VERSION ""

NS_ :

BS_:

BU_: INV U2C VCU BMS INV BMS VCU

BO_ 3221225472 VECTOR__INDEPENDENT_SIG_MSG: 0 Vector__XXX
 SG_ INV_Buffer_Record : 0|8@1+ (1,0) [0|255] "" Vector__XXX
 SG_ INV_Buffer_Segment : 8|8@1+ (1,0) [0|5] "" Vector__XXX
 SG_ INV_Diag_Data_1 : 16|16@1- (1,0) [-32768|32767] "" Vector__XXX
 SG_ INV_Diag_Data_2 : 32|16@1- (1,0) [-32768|32767] "" Vector__XXX
 SG_ INV_Diag_Data_3 : 48|16@1- (1,0) [-32768|32767] "" Vector__XXX

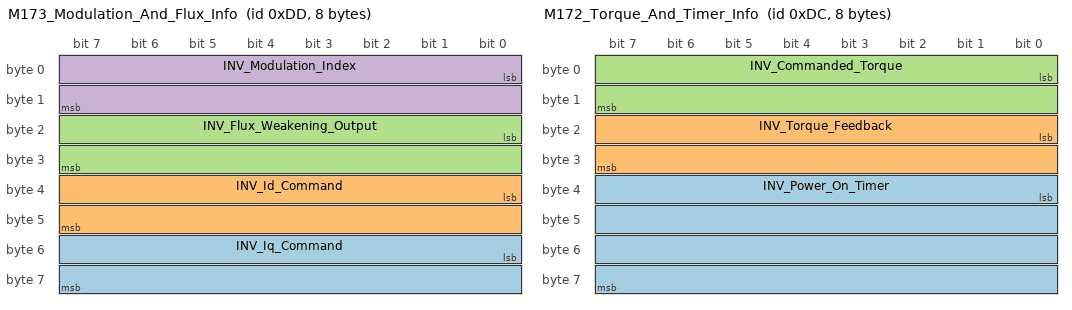
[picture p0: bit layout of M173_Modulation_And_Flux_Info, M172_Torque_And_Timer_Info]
BO_ 221 M173_Modulation_And_Flux_Info: 8 INV
 SG_ INV_Iq_Command : 48|16@1- (0.1,0) [-3276.8|3276.7] "current:A" Vector__XXX
 SG_ INV_Id_Command : 32|16@1- (0.1,0) [-3276.8|3276.7] "current:A" Vector__XXX
 SG_ INV_Flux_Weakening_Output : 16|16@1- (0.1,0) [-3276.8|3276.7] "current:A" Vector__XXX
 SG_ INV_Modulation_Index : 0|16@1- (0.0001,0) [0|3.2767] "" Vector__XXX

BO_ 220 M172_Torque_And_Timer_Info: 8 INV
 SG_ INV_Power_On_Timer : 32|32@1+ (0.003,0) [0|12884800] "time:sec" Vector__XXX
 SG_ INV_Torque_Feedback : 16|16@1- (0.1,0) [-3276.8|3276.7] "torque:N.m" Vector__XXX
 SG_ INV_Commanded_Torque : 0|16@1- (0.1,0) [-3276.8|3276.7] "torque:N.m" Vector__XXX

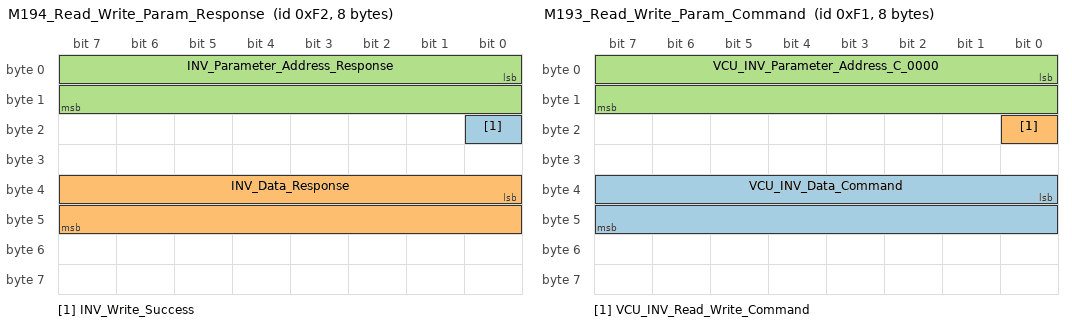
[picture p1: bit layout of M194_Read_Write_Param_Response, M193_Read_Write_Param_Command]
BO_ 242 M194_Read_Write_Param_Response: 8 INV
 SG_ INV_Write_Success : 16|1@1+ (1,0) [0|1] "" Vector__XXX
 SG_ INV_Data_Response : 32|16@1- (1,0) [-32768|32767] "" Vector__XXX
 SG_ INV_Parameter_Address_Response : 0|16@1+ (1,0) [0|65535] "" Vector__XXX

BO_ 241 M193_Read_Write_Param_Command: 8 VCU
 SG_ VCU_INV_Data_Command : 32|16@1- (1,0) [-32768|32767] "" Vector__XXX
 SG_ VCU_INV_Read_Write_Command : 16|1@1+ (1,0) [0|1] "" Vector__XXX
 SG_ VCU_INV_Parameter_Address_C_0000 : 0|16@1+ (1,0) [0|65535] "" Vector__XXX

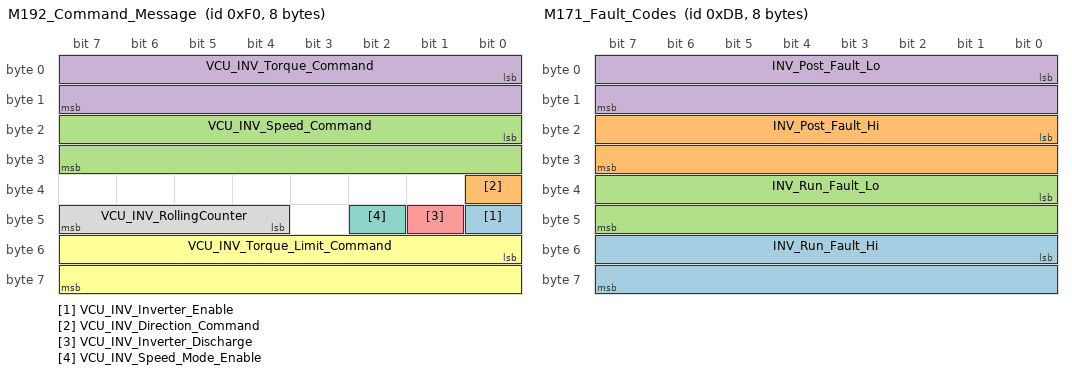
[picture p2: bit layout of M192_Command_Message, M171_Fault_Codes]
BO_ 240 M192_Command_Message: 8 VCU
 SG_ VCU_INV_Inverter_Enable : 40|1@1+ (1,0) [0|1] "" Vector__XXX
 SG_ VCU_INV_Direction_Command : 32|1@1+ (1,0) [0|1] "" Vector__XXX
 SG_ VCU_INV_Speed_Command : 16|16@1- (1,0) [-32768|32767] "angular_speed:rpm" Vector__XXX
 SG_ VCU_INV_Torque_Command : 0|16@1- (0.1,0) [-3276.8|3276.7] "torque:N.m" Vector__XXX
 SG_ VCU_INV_Inverter_Discharge : 41|1@1+ (1,0) [0|1] "" Vector__XXX
 SG_ VCU_INV_Torque_Limit_Command : 48|16@1- (0.1,0) [-3276.8|3276.7] "torque:N.m" Vector__XXX
 SG_ VCU_INV_Speed_Mode_Enable : 42|1@1+ (1,0) [0|1] "" Vector__XXX
 SG_ VCU_INV_RollingCounter : 44|4@1+ (1,0) [0|15] "" Vector__XXX

BO_ 219 M171_Fault_Codes: 8 INV
 SG_ INV_Run_Fault_Hi : 48|16@1+ (1,0) [0|65535] "" Vector__XXX
 SG_ INV_Post_Fault_Hi : 16|16@1+ (1,0) [0|65535] "" Vector__XXX
 SG_ INV_Run_Fault_Lo : 32|16@1+ (1,0) [0|65535] "" Vector__XXX
 SG_ INV_Post_Fault_Lo : 0|16@1+ (1,0) [0|65535] "" Vector__XXX

BO_ 218 M170_Internal_States: 8 INV
 SG_ INV_Direction_Command : 56|1@1+ (1,0) [0|1] "" Vector__XXX
 SG_ INV_Inverter_Enable_State : 48|1@1+ (1,0) [0|1] "" Vector__XXX
 SG_ INV_Relay_3_Status : 26|1@1+ (1,0) [0|1] "" Vector__XXX
 SG_ INV_Relay_4_Status : 27|1@1+ (1,0) [0|1] "" Vector__XXX
 SG_ INV_Relay_2_Status : 25|1@1+ (1,0) [0|1] "" Vector__XXX
 SG_ INV_Inverter_Run_Mode : 32|1@1+ (1,0) [0|1] "" Vector__XXX
 SG_ INV_Inverter_Command_Mode : 40|1@1+ (1,0) [0|1] "" Vector__XXX
 SG_ INV_Relay_1_Status : 24|1@1+ (1,0) [0|1] "" Vector__XXX
 SG_ INV_Inverter_State : 16|8@1+ (1,0) [0|255] "" Vector__XXX
 SG_ INV_VSM_State : 0|8@1+ (1,0) [0|15] "" Vector__XXX
 SG_ INV_Inverter_Enable_Lockout : 55|1@1+ (1,0) [0|1] "" Vector__XXX
 SG_ INV_Inverter_Discharge_State : 37|3@1+ (1,0) [0|7] "" Vector__XXX
 SG_ INV_Relay_5_Status : 28|1@1+ (1,0) [0|1] "" Vector__XXX
 SG_ INV_Relay_6_Status : 29|1@1+ (1,0) [0|1] "" Vector__XXX
 SG_ INV_BMS_Active : 57|1@1+ (1,0) [0|1] "" Vector__XXX
 SG_ INV_BMS_Torque_Limiting : 58|1@1+ (1,0) [0|1] "" Vector__XXX
 SG_ INV_Max_Speed_Limiting : 59|1@1+ (1,0) [0|1] "" Vector__XXX
 SG_ INV_Low_Speed_Limiting : 61|1@1+ (1,0) [0|1] "" Vector__XXX
 SG_ INV_Rolling_Counter : 44|4@1+ (1,0) [0|15] "" Vector__XXX
 SG_ INV_PWM_Frequency : 8|8@1+ (1,0) [0|255] "kHz" Vector__XXX
 SG_ INV_Start_Mode_Active : 54|1@1+ (1,0) [0|1] "" Vector__XXX

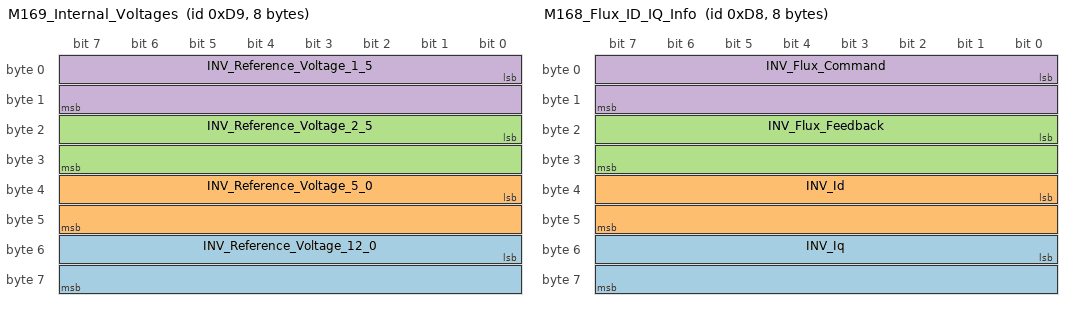
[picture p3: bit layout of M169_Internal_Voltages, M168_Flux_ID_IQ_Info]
BO_ 217 M169_Internal_Voltages: 8 INV
 SG_ INV_Reference_Voltage_12_0 : 48|16@1- (0.01,0) [-327.68|327.67] "voltage:V" Vector__XXX
 SG_ INV_Reference_Voltage_5_0 : 32|16@1- (0.01,0) [-327.68|327.67] "voltage:V" Vector__XXX
 SG_ INV_Reference_Voltage_2_5 : 16|16@1- (0.01,0) [-327.68|327.67] "voltage:V" Vector__XXX
 SG_ INV_Reference_Voltage_1_5 : 0|16@1- (0.01,0) [-327.68|327.67] "voltage:V" Vector__XXX

BO_ 216 M168_Flux_ID_IQ_Info: 8 INV
 SG_ INV_Iq : 48|16@1- (0.1,0) [-3276.8|3276.7] "current:A" Vector__XXX
 SG_ INV_Id : 32|16@1- (0.1,0) [-3276.8|3276.7] "current:A" Vector__XXX
 SG_ INV_Flux_Feedback : 16|16@1- (0.001,0) [-32.768|32.767] "flux:Wb" Vector__XXX
 SG_ INV_Flux_Command : 0|16@1- (0.001,0) [-32.768|32.767] "flux:Wb" Vector__XXX

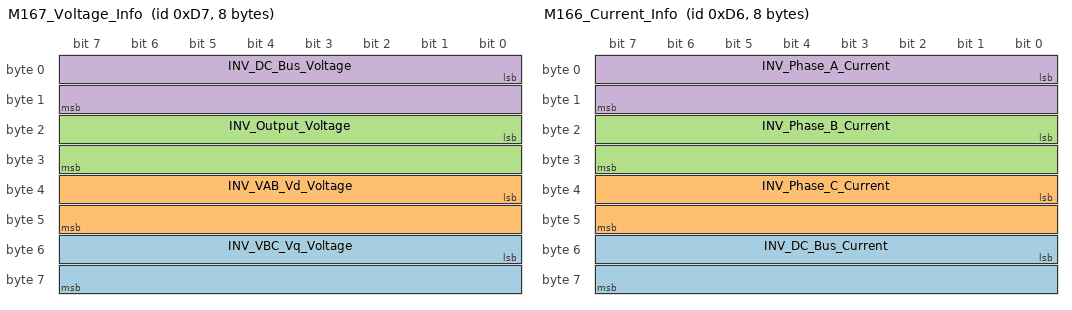
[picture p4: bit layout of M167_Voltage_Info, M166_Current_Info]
BO_ 215 M167_Voltage_Info: 8 INV
 SG_ INV_VBC_Vq_Voltage : 48|16@1- (0.1,0) [-3276.8|3276.7] "voltage:V" Vector__XXX
 SG_ INV_VAB_Vd_Voltage : 32|16@1- (0.1,0) [-3276.8|3276.7] "voltage:V" Vector__XXX
 SG_ INV_Output_Voltage : 16|16@1- (0.1,0) [-3276.8|3276.7] "voltage:V" Vector__XXX
 SG_ INV_DC_Bus_Voltage : 0|16@1- (0.1,0) [-3276.8|3276.7] "voltage:V" Vector__XXX

BO_ 214 M166_Current_Info: 8 INV
 SG_ INV_DC_Bus_Current : 48|16@1- (0.1,0) [-3276.8|3276.7] "current:A" Vector__XXX
 SG_ INV_Phase_C_Current : 32|16@1- (0.1,0) [-3276.8|3276.7] "current:A" Vector__XXX
 SG_ INV_Phase_B_Current : 16|16@1- (0.1,0) [-3276.8|3276.7] "current:A" Vector__XXX
 SG_ INV_Phase_A_Current : 0|16@1- (0.1,0) [-3276.8|3276.7] "current:A" Vector__XXX

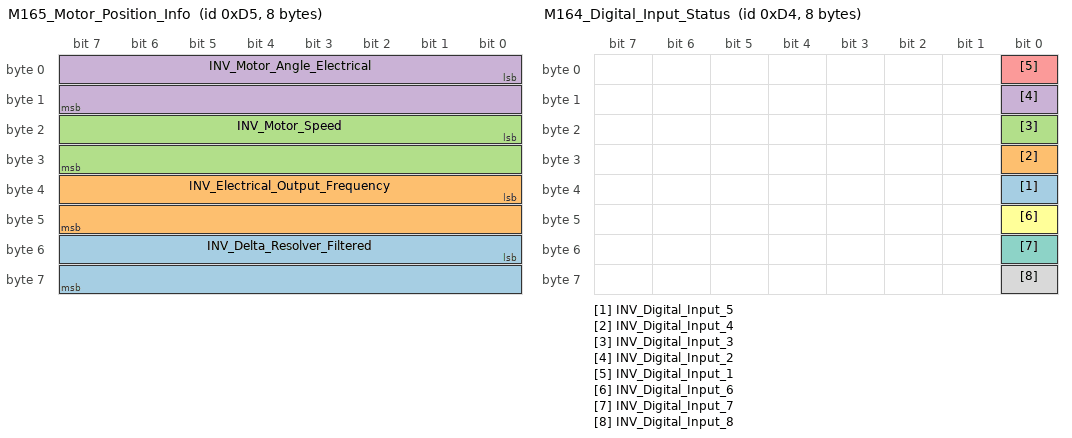
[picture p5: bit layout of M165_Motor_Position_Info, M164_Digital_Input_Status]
BO_ 213 M165_Motor_Position_Info: 8 INV
 SG_ INV_Delta_Resolver_Filtered : 48|16@1- (0.1,0) [-3276.8|3276.7] "angle:deg" Vector__XXX
 SG_ INV_Electrical_Output_Frequency : 32|16@1- (0.1,0) [-3276.8|3276.7] "frequency:Hz" Vector__XXX
 SG_ INV_Motor_Speed : 16|16@1- (1,0) [-32768|32767] "angular_speed:rpm" Vector__XXX
 SG_ INV_Motor_Angle_Electrical : 0|16@1+ (0.1,0) [0|6553.5] "angle:deg" Vector__XXX

BO_ 212 M164_Digital_Input_Status: 8 INV
 SG_ INV_Digital_Input_5 : 32|1@1+ (1,0) [0|1] "" Vector__XXX
 SG_ INV_Digital_Input_4 : 24|1@1+ (1,0) [0|1] "" Vector__XXX
 SG_ INV_Digital_Input_3 : 16|1@1+ (1,0) [0|1] "" Vector__XXX
 SG_ INV_Digital_Input_2 : 8|1@1+ (1,0) [0|1] "" Vector__XXX
 SG_ INV_Digital_Input_1 : 0|1@1+ (1,0) [0|1] "" Vector__XXX
 SG_ INV_Digital_Input_6 : 40|1@1+ (1,0) [0|1] "" Vector__XXX
 SG_ INV_Digital_Input_7 : 48|1@1+ (1,0) [0|1] "" Vector__XXX
 SG_ INV_Digital_Input_8 : 56|1@1+ (1,0) [0|1] "" Vector__XXX

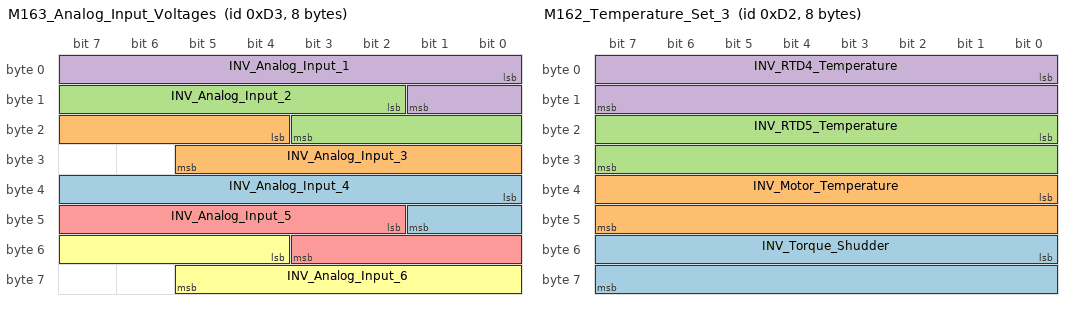
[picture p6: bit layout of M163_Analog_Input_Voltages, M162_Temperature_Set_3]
BO_ 211 M163_Analog_Input_Voltages: 8 INV
 SG_ INV_Analog_Input_4 : 32|10@1+ (0.01,0) [0|10.23] "voltage:V" Vector__XXX
 SG_ INV_Analog_Input_3 : 20|10@1+ (0.01,0) [0|10.23] "voltage:V" Vector__XXX
 SG_ INV_Analog_Input_2 : 10|10@1+ (0.01,0) [0|10.23] "voltage:V" Vector__XXX
 SG_ INV_Analog_Input_1 : 0|10@1+ (0.01,0) [0|10.23] "voltage:V" Vector__XXX
 SG_ INV_Analog_Input_5 : 42|10@1+ (0.01,0) [0|10.23] "voltage:V" Vector__XXX
 SG_ INV_Analog_Input_6 : 52|10@1+ (0.01,0) [0|10.23] "voltage:V" Vector__XXX

BO_ 210 M162_Temperature_Set_3: 8 INV
 SG_ INV_Torque_Shudder : 48|16@1- (0.1,0) [-3276.8|3276.7] "torque:N.m" Vector__XXX
 SG_ INV_Motor_Temperature : 32|16@1- (0.1,0) [-3276.8|3276.7] "temperature:C" Vector__XXX
 SG_ INV_RTD5_Temperature : 16|16@1- (0.1,0) [-3276.8|3276.7] "temperature:C" Vector__XXX
 SG_ INV_RTD4_Temperature : 0|16@1- (0.1,0) [-3276.8|3276.7] "temperature:C" Vector__XXX

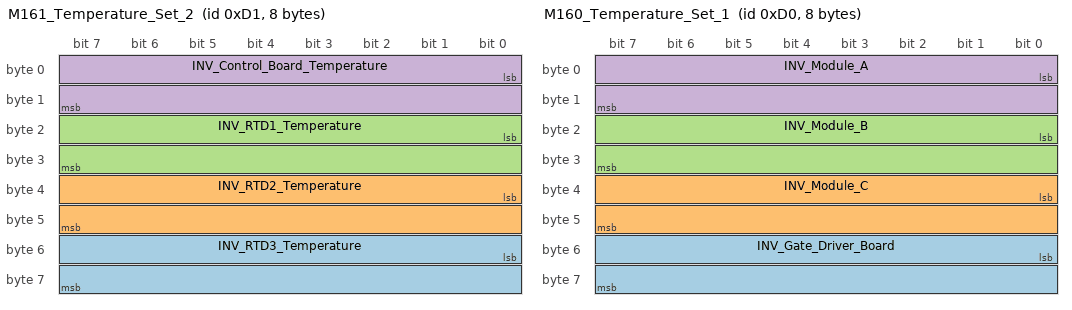
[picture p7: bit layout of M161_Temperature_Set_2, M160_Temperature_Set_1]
BO_ 209 M161_Temperature_Set_2: 8 INV
 SG_ INV_RTD3_Temperature : 48|16@1- (0.1,0) [-3276.8|3276.7] "temperature:C" Vector__XXX
 SG_ INV_RTD2_Temperature : 32|16@1- (0.1,0) [-3276.8|3276.7] "temperature:C" Vector__XXX
 SG_ INV_RTD1_Temperature : 16|16@1- (0.1,0) [-3276.8|3276.7] "temperature:C" Vector__XXX
 SG_ INV_Control_Board_Temperature : 0|16@1- (0.1,0) [-3276.8|3276.7] "temperature:C" Vector__XXX

BO_ 208 M160_Temperature_Set_1: 8 INV
 SG_ INV_Gate_Driver_Board : 48|16@1- (0.1,0) [-3276.8|3276.7] "temperature:C" Vector__XXX
 SG_ INV_Module_C : 32|16@1- (0.1,0) [-3276.8|3276.7] "temperature:C" Vector__XXX
 SG_ INV_Module_B : 16|16@1- (0.1,0) [-3276.8|3276.7] "temperature:C" Vector__XXX
 SG_ INV_Module_A : 0|16@1- (0.1,0) [-3276.8|3276.7] "temperature:C" Vector__XXX

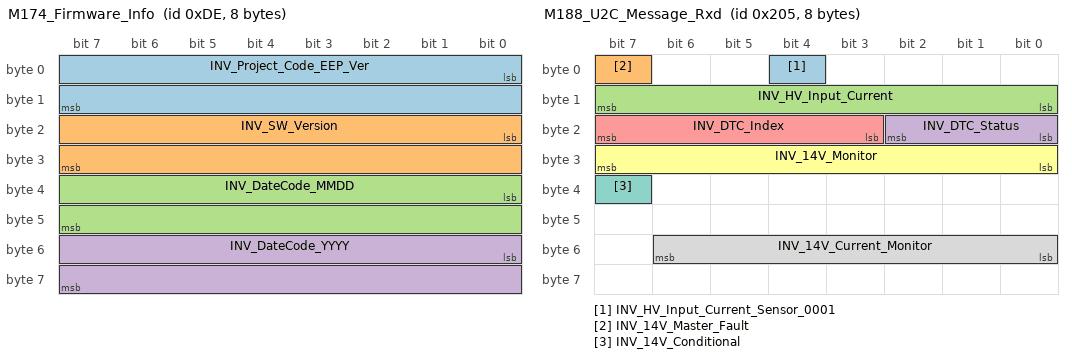
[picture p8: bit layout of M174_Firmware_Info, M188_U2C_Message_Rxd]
BO_ 222 M174_Firmware_Info: 8 INV
 SG_ INV_Project_Code_EEP_Ver : 0|16@1+ (1,0) [0|65535] "" Vector__XXX
 SG_ INV_SW_Version : 16|16@1+ (1,0) [0|65535] "" Vector__XXX
 SG_ INV_DateCode_MMDD : 32|16@1+ (1,0) [0|65535] "" Vector__XXX
 SG_ INV_DateCode_YYYY : 48|16@1+ (1,0) [0|65535] "" Vector__XXX

BO_ 519 M187_U2C_Command_Txd: 8 INV
 SG_ U2C_ID_Byte : 0|8@1+ (1,0) [0|255] "" Vector__XXX
 SG_ U2C_Setpoint_Calc : 8|8@1+ (1,0) [0|255] "" Vector__XXX

BO_ 517 M188_U2C_Message_Rxd: 8 U2C
 SG_ INV_HV_Input_Current_Sensor_0001 : 4|1@1+ (1,0) [0|1] "" Vector__XXX
 SG_ INV_14V_Master_Fault : 7|1@1+ (1,0) [0|1] "" Vector__XXX
 SG_ INV_HV_Input_Current : 8|8@1+ (1,0) [0|255] "" Vector__XXX
 SG_ INV_DTC_Status : 16|3@1+ (1,0) [0|7] "" Vector__XXX
 SG_ INV_DTC_Index : 19|5@1+ (1,0) [0|31] "" Vector__XXX
 SG_ INV_14V_Monitor : 24|8@1+ (1,0) [0|255] "" Vector__XXX
 SG_ INV_14V_Conditional : 39|1@1+ (1,0) [0|1] "" Vector__XXX
 SG_ INV_14V_Current_Monitor : 48|7@1+ (1,0) [0|127] "" Vector__XXX

BO_ 562 BMS_Current_Limit: 8 BMS
 SG_ INV_Max_Discharge_Current : 0|16@1+ (1,0) [0|1000] "current:A" Vector__XXX
 SG_ INV_Max_Charge_Current : 16|16@1+ (1,0) [0|1000] "current:A" Vector__XXX

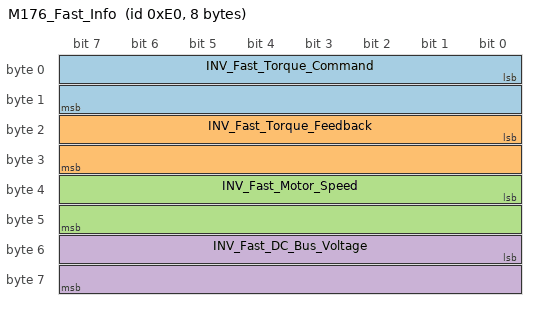
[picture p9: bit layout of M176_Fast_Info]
BO_ 224 M176_Fast_Info: 8 INV
 SG_ INV_Fast_Torque_Command : 0|16@1- (0.1,0) [-3276.8|3276.7] "torque:N.m" Vector__XXX
 SG_ INV_Fast_Torque_Feedback : 16|16@1- (0.1,0) [-3276.8|3276.7] "torque:N.m" Vector__XXX
 SG_ INV_Fast_Motor_Speed : 32|16@1- (1,0) [-32768|32767] "angular_speed:rpm" Vector__XXX
 SG_ INV_Fast_DC_Bus_Voltage : 48|16@1- (0.1,0) [-3276.8|3276.7] "voltage:V" Vector__XXX

BO_ 223 M175_Diag_Data_Message: 8 INV
 SG_ INV_Diag_Record : 0|8@1+ (1,0) [0|160] "" Vector__XXX
 SG_ INV_Diag_Segment M : 8|8@1+ (1,0) [0|5] "" Vector__XXX
 SG_ INV_Diag_Gamma_Resolver m0 : 16|16@1- (0.1,0) [0|360] "angle:deg" Vector__XXX
 SG_ INV_Diag_Gamma_Observer m0 : 32|16@1- (0.1,0) [0|360] "angle:deg" Vector__XXX
 SG_ INV_Diag_Sin m0 : 48|16@1- (1,0) [-5|5] "voltage:V" Vector__XXX
 SG_ INV_Diag_Cos m1 : 16|16@1- (1,0) [-5|5] "voltage:V" Vector__XXX
 SG_ INV_Diag_Ia m1 : 32|16@1- (0.1,0) [-2000|2000] "current:A" Vector__XXX
 SG_ INV_Diag_Ib m1 : 48|16@1- (0.1,0) [-2000|2000] "current:A" Vector__XXX
 SG_ INV_Diag_Ic m2 : 16|16@1- (0.1,0) [-2000|2000] "current:A" Vector__XXX
 SG_ INV_Diag_Vdc m2 : 32|16@1- (0.1,0) [0|1000] "voltage:V" Vector__XXX
 SG_ INV_Diag_Iq_cmd m2 : 48|16@1- (0.1,0) [-2000|2000] "current:A" Vector__XXX
 SG_ INV_Diag_Id_cmd m3 : 16|16@1- (0.1,0) [-2000|2000] "current:A" Vector__XXX
 SG_ INV_Diag_Mod_Index m3 : 32|16@1- (0.0001,0) [0|2] "" Vector__XXX
 SG_ INV_Diag_FW_Output m3 : 48|16@1- (0.1,0) [-2000|2000] "current:A" Vector__XXX
 SG_ INV_Diag_Vq_Cmd m4 : 16|16@1- (0.1,0) [-1000|1000] "voltage:V" Vector__XXX
 SG_ INV_Diag_Vd_Cmd m4 : 32|16@1- (0.1,0) [-1000|1000] "voltage:V" Vector__XXX
 SG_ INV_Diag_Vqs_Cmd m4 : 48|16@1- (0.1,0) [-1000|1000] "voltage:V" Vector__XXX
 SG_ INV_Diag_12V m5 : 16|16@1+ (0.01,0) [0|36] "voltage:V" Vector__XXX
 SG_ INV_Diag_Run_Faults_Lo m5 : 32|16@1+ (1,0) [0|65535] "" Vector__XXX
 SG_ INV_Diag_Run_Faults_Hi m5 : 48|16@1+ (1,0) [0|65535] "" Vector__XXX

BO_ 225 M177_Torque_Capability: 8 INV
 SG_ INV_Torque_Capability_Motor : 0|16@1- (0.1,0) [0|3276.7] "torque:N.m" Vector__XXX
 SG_ INV_Torque_Capability_Regen : 16|16@1- (0.1,0) [-3276.8|0] "torque:N.m" Vector__XXX

CM_ BU_ INV "The Cascadia Motion inverter";
CM_ BU_ U2C "Delphi DC/DC Converter";
CM_ BU_ VCU "The system vehicle control unit";
CM_ BU_ BMS "BMS Master";
CM_ SG_ 221 INV_Iq_Command "The commanded Q-axis current";
CM_ SG_ 221 INV_Id_Command "The commanded D-axis current";
CM_ SG_ 221 INV_Flux_Weakening_Output "This is the current output of the flux regulator.";
CM_ SG_ 221 INV_Modulation_Index "This is the modulation index. The scale factor is x100. To get the actual modulation index divide the value by 100.";
CM_ SG_ 220 INV_Power_On_Timer "Updated every 3 msec. This will roll over in approximately 150 days!";
CM_ SG_ 220 INV_Torque_Feedback "Estimated motor torque feedback";
CM_ SG_ 220 INV_Commanded_Torque "The commanded Torque";
CM_ BO_ 242 "The inverter response to each Parameter message that is received.";
CM_ SG_ 242 INV_Write_Success "0=Write failure, 1=Success";
CM_ SG_ 242 INV_Data_Response "All EEPROM data is 16 bits and is contained in bytes 4 and 5. Bytes 6 and 7 should be ignored.";
CM_ SG_ 242 INV_Parameter_Address_Response "Valid EEPROM Parameter CAN addresses are between 100 and 499.";
CM_ BO_ 241 "Parameter Message sent as needed by VCU to request info, change EEPROM, or command a function.";
CM_ BO_ 240 "The command message is used to transmit data to the controller. This message is sent from a user supplied external controller to the PMxxx controller.";
CM_ SG_ 219 INV_Run_Fault_Hi "Each bit represents a fault. Please refer to PM100 Users Manual for details.";
CM_ SG_ 219 INV_Post_Fault_Hi "Each bit represents a fault. Please refer to PM100 Users Manual for details.";
CM_ SG_ 219 INV_Run_Fault_Lo "Each bit represents a fault. Please refer to PM100 Users Manual for details.";
CM_ SG_ 219 INV_Post_Fault_Lo "Each bit represents a fault. Please refer to PM100 Users Manual for details.";
CM_ SG_ 218 INV_Direction_Command "1 = Forward
0 = 'Reverse' if inverter enabled  & 'Stopped' if inverter is disabled";
CM_ SG_ 218 INV_Inverter_Enable_State "0=Inverter Disabled, 
1=Inverter Enabled";
CM_ SG_ 218 INV_Relay_3_Status "0=OFF, 1=ON";
CM_ SG_ 218 INV_Relay_4_Status "0=OFF, 1=ON";
CM_ SG_ 218 INV_Relay_2_Status "0=OFF, 1=ON";
CM_ SG_ 218 INV_Inverter_Run_Mode "0=Torque Mode, 1=Speed Mode";
CM_ SG_ 218 INV_Inverter_Command_Mode "0=CAN mode, 1=VSM mode";
CM_ SG_ 218 INV_Relay_1_Status "0=OFF, 1=ON";
CM_ SG_ 218 INV_Inverter_State "Different states for the inverter state machine";
CM_ SG_ 218 INV_VSM_State "Different states for the vehicle state machine";
CM_ SG_ 218 INV_Inverter_Enable_Lockout "0=Lockout Disabled, 1=Lockout Enabled";
CM_ SG_ 218 INV_Inverter_Discharge_State "0 = Disabled, 1 = Enabled, 2 = Speed Check, 3 = Active, 4 = Complete";
CM_ SG_ 218 INV_Relay_5_Status "0=OFF, 1=ON";
CM_ SG_ 218 INV_Relay_6_Status "0=OFF, 1=ON";
CM_ SG_ 218 INV_BMS_Active "0 = BMS Not Active, 1 = BMS Active";
CM_ SG_ 218 INV_BMS_Torque_Limiting "0 = Not Limiting, 1 = Limiting";
CM_ SG_ 218 INV_Max_Speed_Limiting "0 = Not Limiting, 1 = torque limiting due to maximum speed";
CM_ SG_ 218 INV_Low_Speed_Limiting "0 = Not Limiting, 1 = Current limiting due to low motor speed";
CM_ SG_ 218 INV_Rolling_Counter "The current rolling counter value.";
CM_ SG_ 218 INV_PWM_Frequency "The inverter PWM frequency";
CM_ SG_ 218 INV_Start_Mode_Active "If in Key Switch Mode 1 then indicates status of Start input being applied.  0 = not active, 1 = active";
CM_ SG_ 217 INV_Reference_Voltage_12_0 "12V Input Voltage";
CM_ SG_ 217 INV_Reference_Voltage_5_0 "Transducer voltage";
CM_ SG_ 217 INV_Reference_Voltage_2_5 "Internal reference voltage";
CM_ SG_ 217 INV_Reference_Voltage_1_5 "Internal reference voltage";
CM_ SG_ 216 INV_Iq "The measured Iq current";
CM_ SG_ 216 INV_Id "The measured Id current";
CM_ SG_ 216 INV_Flux_Feedback "The estimated flux";
CM_ SG_ 216 INV_Flux_Command "The commanded flux";
CM_ SG_ 215 INV_VBC_Vq_Voltage "Measured value of the voltage between Phase B and Phase C";
CM_ SG_ 215 INV_VAB_Vd_Voltage "Measured value of the voltage betwen phase A and Phase B";
CM_ SG_ 215 INV_Output_Voltage "The calculated value of the output voltage, in peak line-neutral volts";
CM_ SG_ 215 INV_DC_Bus_Voltage "The actual measured value of the DC bus voltage";
CM_ SG_ 214 INV_DC_Bus_Current "The Calculated DC Bus Current";
CM_ SG_ 214 INV_Phase_C_Current "The measured value of Phase C current";
CM_ SG_ 214 INV_Phase_B_Current "The measured value of Phase B current";
CM_ SG_ 214 INV_Phase_A_Current "The measured value of Phase A current";
CM_ SG_ 213 INV_Delta_Resolver_Filtered "Used in calibration of resolver angle adjustment.";
CM_ SG_ 213 INV_Electrical_Output_Frequency "The actual electrical frequency of the inverter";
CM_ SG_ 213 INV_Motor_Speed "The measured speed of the motor";
CM_ SG_ 213 INV_Motor_Angle_Electrical "The Electrical Angle of the motor as read by the encoder or resolver";
CM_ SG_ 212 INV_Digital_Input_5 "Status of Digital Input #5";
CM_ SG_ 212 INV_Digital_Input_4 "Status of Digital Input #4";
CM_ SG_ 212 INV_Digital_Input_3 "Status of Digital Input #3";
CM_ SG_ 212 INV_Digital_Input_2 "Status of Digital Input #2";
CM_ SG_ 212 INV_Digital_Input_1 "Status of Digital Input #1";
CM_ SG_ 212 INV_Digital_Input_6 "Status of Digital Input #6";
CM_ SG_ 212 INV_Digital_Input_7 "Status of Digital Input #7";
CM_ SG_ 212 INV_Digital_Input_8 "Status of Digital Input #8";
CM_ SG_ 211 INV_Analog_Input_4 "Voltage on Analog Input #4";
CM_ SG_ 211 INV_Analog_Input_3 "Voltage on Analog Input #3";
CM_ SG_ 211 INV_Analog_Input_2 "Voltage on Analog Input #2";
CM_ SG_ 211 INV_Analog_Input_1 "Voltage on Analog Input #1";
CM_ SG_ 211 INV_Analog_Input_5 "Voltage on Analog Input #5";
CM_ SG_ 211 INV_Analog_Input_6 "Voltage on Analog Input #6";
CM_ SG_ 210 INV_Torque_Shudder "Shudder compensation value of torque";
CM_ SG_ 210 INV_Motor_Temperature "Motor Temperature Sensor";
CM_ SG_ 210 INV_RTD5_Temperature "RTD 5 (PT100) Temperature (Gen 2 only)";
CM_ SG_ 210 INV_RTD4_Temperature "RTD 4 (PT100) Temperature (Gen 2 only)";
CM_ SG_ 209 INV_RTD3_Temperature "RTD input 3 (PT1000) Temperature";
CM_ SG_ 209 INV_RTD2_Temperature "RTD input 2 (PT1000) Temperature";
CM_ SG_ 209 INV_RTD1_Temperature "RTD input 1 (PT1000) Temperature";
CM_ SG_ 209 INV_Control_Board_Temperature "Control Board Temperature";
CM_ SG_ 208 INV_Gate_Driver_Board "Gate Driver Board Temperature";
CM_ SG_ 208 INV_Module_C "IGBT Module C Temperature";
CM_ SG_ 208 INV_Module_B "IGBT Module B Temperature";
CM_ SG_ 208 INV_Module_A "IGBT Module A Temperature";
CM_ BO_ 519 "Enable message sent to Delphi DC/DC converter.";
CM_ BO_ 517 "Response from Delphi DC/DC converter.";
CM_ BO_ 562 "Message sent by BMS for inverter DC current limiting.";
CM_ SG_ 562 INV_Max_Discharge_Current "Maximum discharge current from BMS";
CM_ SG_ 562 INV_Max_Charge_Current "Maximum charge current from BMS";
CM_ BO_ 224 "To enable fast message set CAN ACTIVE MSGS HI WORD to 0xFFFE.  Setting to default value of 0xFFFF will disable the fast message.";
CM_ SG_ 225 INV_Torque_Capability_Motor "The motoring torque capability of the inverter given the current operating point.";
CM_ SG_ 225 INV_Torque_Capability_Regen "The regen torque capability of the inverter given the current operating point.";
BA_DEF_ BO_  "GenMsgCycleTime" INT 0 100000;
BA_DEF_  "BusType" STRING ;
BA_DEF_ SG_  "SystemSignalLongSymbol" STRING ;
BA_DEF_DEF_  "GenMsgCycleTime" 0;
BA_DEF_DEF_  "BusType" "CAN";
BA_DEF_DEF_  "SystemSignalLongSymbol" "";
BA_ "GenMsgCycleTime" BO_ 220 10;
BA_ "SystemSignalLongSymbol" SG_ 241 VCU_INV_Parameter_Address_C_0000 "VCU_INV_Parameter_Address_Command";
BA_ "GenMsgCycleTime" BO_ 240 5;
BA_ "GenMsgCycleTime" BO_ 219 100;
BA_ "GenMsgCycleTime" BO_ 218 100;
BA_ "GenMsgCycleTime" BO_ 217 100;
BA_ "GenMsgCycleTime" BO_ 216 10;
BA_ "GenMsgCycleTime" BO_ 215 10;
BA_ "GenMsgCycleTime" BO_ 214 10;
BA_ "GenMsgCycleTime" BO_ 213 10;
BA_ "GenMsgCycleTime" BO_ 212 10;
BA_ "GenMsgCycleTime" BO_ 211 10;
BA_ "GenMsgCycleTime" BO_ 210 100;
BA_ "GenMsgCycleTime" BO_ 209 100;
BA_ "GenMsgCycleTime" BO_ 208 100;
BA_ "SystemSignalLongSymbol" SG_ 517 INV_HV_Input_Current_Sensor_0001 "INV_HV_Input_Current_Sensor_Validity";
BA_ "GenMsgCycleTime" BO_ 224 3;
BA_ "GenMsgCycleTime" BO_ 223 3;
BA_ "GenMsgCycleTime" BO_ 225 10;
VAL_ 218 INV_Inverter_State 0 "Power up" 1 "Stop" 2 "Open Loop" 3 "Closed Loop" 4 "Internal State" 5 "Internal State" 6 "Internal State" 7 "Internal State" 8 "Idle Run" 9 "Idle Stop" 10 "Internal State" 11 "Intern State" 12 "Internal State" ;
VAL_ 218 INV_VSM_State 0 "VSM Start State" 1 "Pre-Charge Init state" 2 "pre-charge active state" 3 "pre-charge complete state" 4 "VSM wait state" 5 "VSM ready state" 6 "Motor Running State" 7 "blink fault code state" 14 "Shutdown state for Key Switch Mode 1" 15 "Reset the inverter" ;
